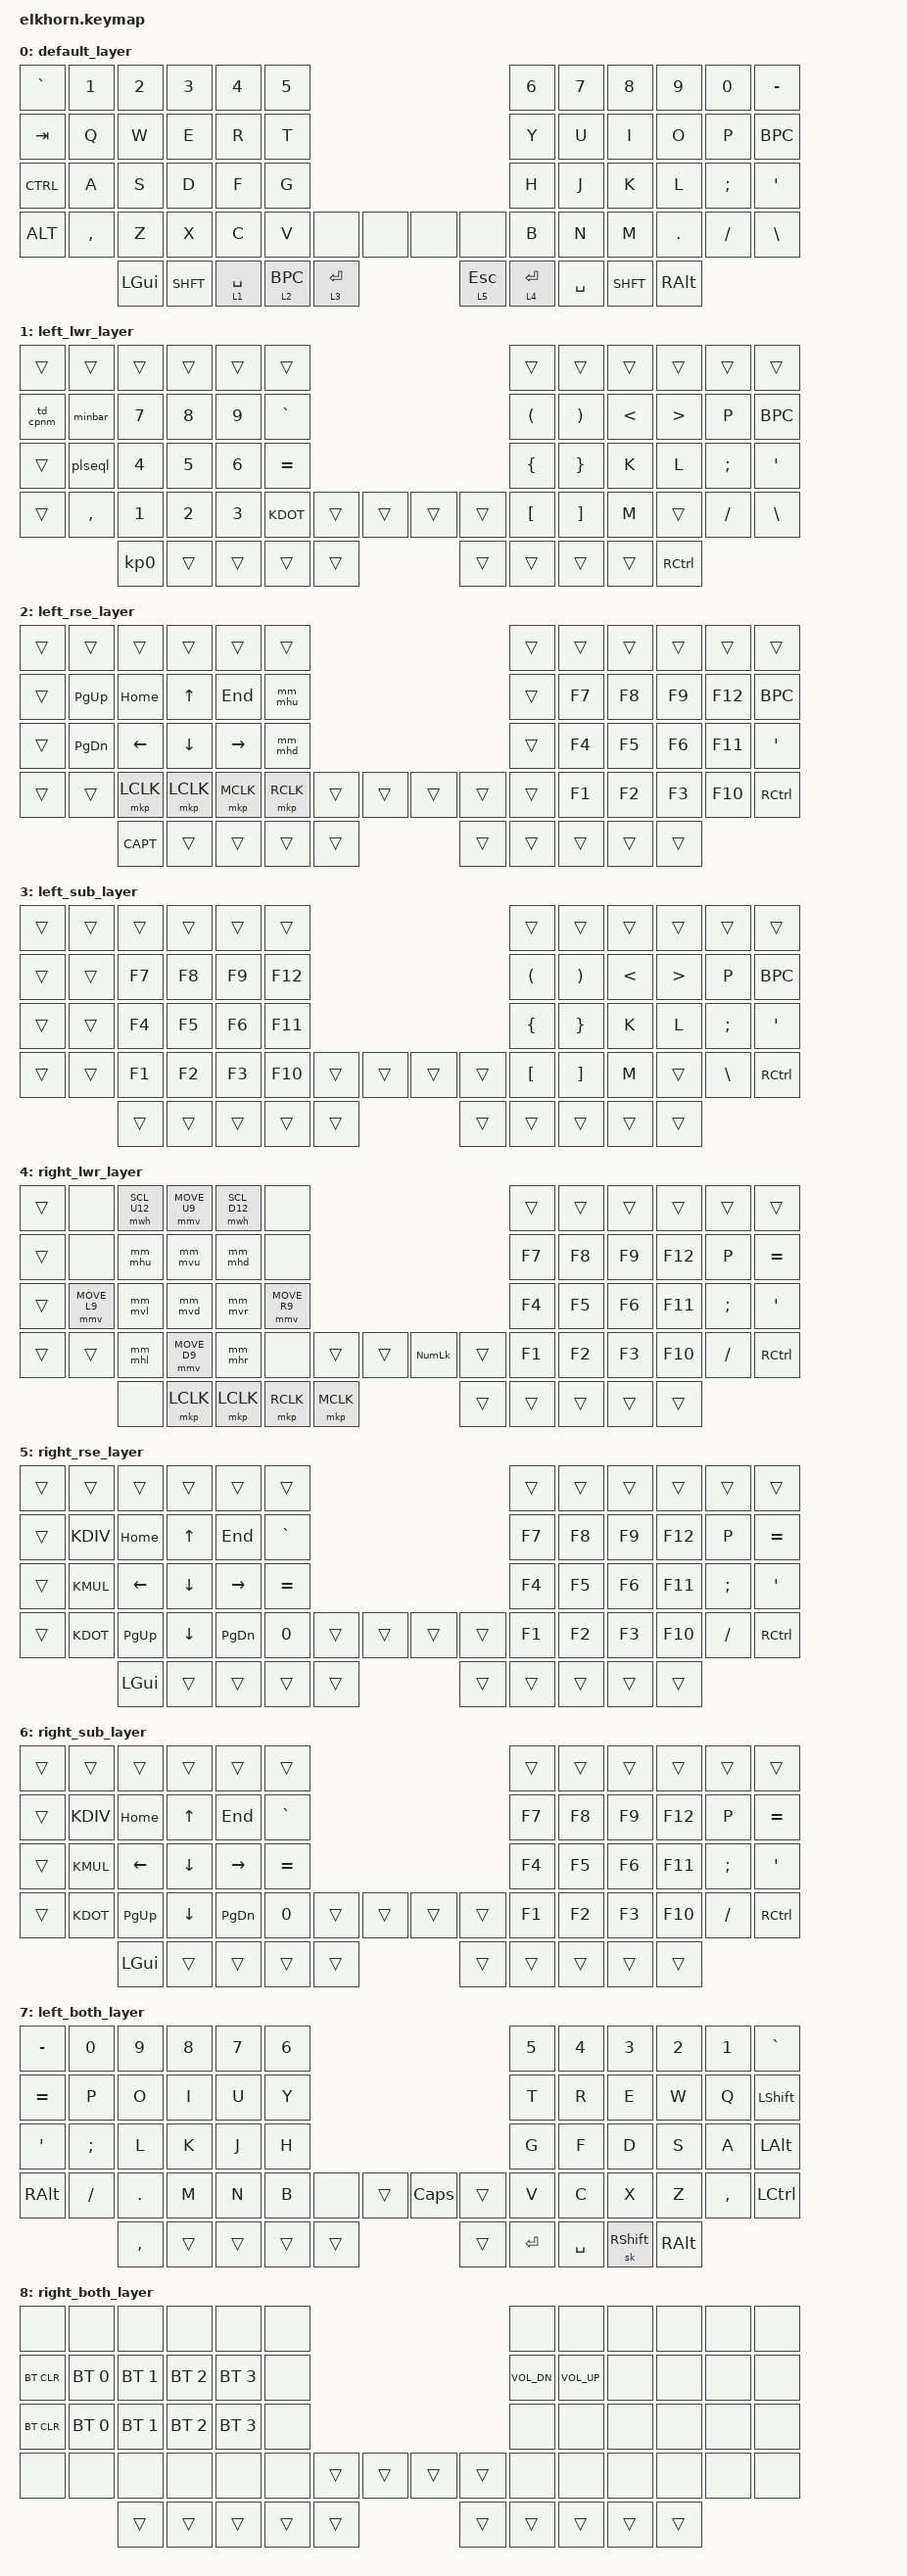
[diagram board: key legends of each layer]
#include <behaviors.dtsi>
#include <dt-bindings/zmk/keys.h>
#include <dt-bindings/zmk/outputs.h>
#include <dt-bindings/zmk/bt.h>
#include <dt-bindings/zmk/mouse.h>

#define HM_TAPPING_TERM 300
#define HM_TAPPING_TERM_FAST 200
#define HM_PRIOR_IDLE 0

#define COMBO_TERM_FAST 35
#define COMBO_TERM_SLOW 40
#define COMBO_PRIOR_IDLE 100

#define MOUSE_MOVE_NEG_DEFAULT -300
#define MOUSE_MOVE_DEFAULT 300
#define MOUSE_MOVE_NEG_FAST -3000 
#define MOUSE_MOVE_FAST 3000 

#define SHFT LSHFT 
#define CTRL LCTRL
#define ALT LALT
#define SPC SPACE
#define BPC BACKSPACE

#define KMIN KP_MINUS
#define KPLS KP_PLUS
#define KMUL KP_MULTIPLY
#define KDIV KP_DIVIDE
#define KDOT KP_DOT
#define KNUM KP_NUM

#define CL CAPS

#define VDN C_VOL_DN
#define VUP C_VOL_UP
#define CALC C_AL_CALC

#define MOVE_U MOVE_VERT(-200)
#define MOVE_D MOVE_VERT(200)
#define MOVE_L MOVE_HOR(-200)
#define MOVE_R MOVE_HOR(200)
#define MOVE_U9 MOVE_VERT(-900)
#define MOVE_D9 MOVE_VERT(900)
#define MOVE_L9 MOVE_HOR(-900)
#define MOVE_R9 MOVE_HOR(900)
#define SCL_U SCROLL_VERT(17)
#define SCL_D SCROLL_VERT(-17)
#define SCL_L SCROLL_HOR(-17)
#define SCL_R SCROLL_HOR(17)
#define SCL_U12 SCROLL_VERT(18)
#define SCL_D12 SCROLL_VERT(-18)
#define SCL_L12 SCROLL_HOR(-18)
#define SCL_R12 SCROLL_HOR(18)



&mmv {
    time-to-max-speed-ms = <0>;
    acceleration-exponent=<0>;
};

&mwh {
    time-to-max-speed-ms = <0>;
    acceleration-exponent=<0>;
};
&mt {
    tapping-term-ms = <100>;
}; 

&sk {
    release-after-ms = <100>;
    quick-release;
}; 

/ {
    chosen {
        zmk,matrix_transform = &default_transform;
    };
};

/ {
    behaviors {
        ht: hold_tab {
            compatible = "zmk,behavior-hold-tap";
            label = "HOLD_TAB";
            #binding-cells = <2>;
            
            flavor = "balanced";
            tapping-term-ms = <HM_TAPPING_TERM_FAST>;
            quick-tap-ms = <0>;
            require-prior-idle-ms = <HM_PRIOR_IDLE>;

            bindings = <&kp>, <&kp>;
        };
        
        hd: hold_mod {
            compatible = "zmk,behavior-hold-tap";
            label = "HOLD_MOD";
            #binding-cells = <2>;
            
            flavor = "balanced";
            tapping-term-ms = <HM_TAPPING_TERM_FAST>;
            quick-tap-ms = <0>;
            require-prior-idle-ms = <HM_PRIOR_IDLE>;

            bindings = <&mo>, <&kp>;
        };

        
        minbar: mod_morph_minus_underbar {
            compatible = "zmk,behavior-mod-morph";
            label="MOD_MORPH_MINUS_UNDERBAR";
            #binding-cells = <0>;
            bindings = <&kp KP_MINUS>, <&kp UNDERSCORE>;
            mods = <(MOD_LSFT)>;
        };
        plseql: mod_morph_plus_equal {
            compatible = "zmk,behavior-mod-morph";
            label="MOD_MORPH_PLUS_EQUAL";
            #binding-cells = <0>;
            bindings = <&kp KP_PLUS>, <&kp EQUAL>;
            mods = <(MOD_LSFT)>;
        };

        td_cpnm: tap_dance_caps_kpnum{
            compatible = "zmk,behavior-tap-dance";
            label = "TAP_DANCE_CAPS_KPNUM";
            #binding-cells = <0>;
            tapping-term-ms = <100>;
            bindings = <&kp CAPS>,  <&kp KP_NUM>;
        };
        
        mm_mvu: mod_morph_mvu{
            compatible = "zmk,behavior-mod-morph";
            label = "MOD_MORPH_MVU";
            #binding-cells = <0>;
            bindings = <&mmv MOVE_VERT(MOUSE_MOVE_NEG_DEFAULT)>,  <&mmv MOVE_VERT(MOUSE_MOVE_NEG_FAST)>;
            mods = <(MOD_LALT)>;
        };
        mm_mvd: mod_morph_mvd{
            compatible = "zmk,behavior-mod-morph";
            label = "MOD_MORPH_MVD";
            #binding-cells = <0>;
            bindings = <&mmv MOVE_VERT(MOUSE_MOVE_DEFAULT)>,  <&mmv MOVE_VERT(MOUSE_MOVE_FAST)>;
            mods = <(MOD_LALT)>;
        };
        mm_mvl: mod_morph_mvl{
            compatible = "zmk,behavior-mod-morph";
            label = "MOD_MORPH_MVL";
            #binding-cells = <0>;
            bindings = <&mmv MOVE_HOR(MOUSE_MOVE_NEG_DEFAULT)>,  <&mmv MOVE_HOR(MOUSE_MOVE_NEG_FAST)>;
            mods = <(MOD_LALT)>;
        };
        mm_mvr: mod_morph_mvr{
            compatible = "zmk,behavior-mod-morph";
            label = "MOD_MORPH_MVR";
            #binding-cells = <0>;
            bindings = <&mmv MOVE_HOR(MOUSE_MOVE_DEFAULT)>,  <&mmv MOVE_HOR(MOUSE_MOVE_FAST)>;
            mods = <(MOD_LALT)>;
        };
        mm_mhu: mod_morph_mhu{
            compatible = "zmk,behavior-mod-morph";
            label = "MOD_MORPH_MHU";
            #binding-cells = <0>;
            bindings = <&mwh SCL_U>,  <&mwh SCL_U12>;
            mods = <(MOD_LALT)>;
        };
        mm_mhd: mod_morph_mhd{
            compatible = "zmk,behavior-mod-morph";
            label = "MOD_MORPH_MHD";
            #binding-cells = <0>;
            bindings = <&mwh SCL_D>,  <&mwh SCL_D12>;
            mods = <(MOD_LALT)>;
        };
        mm_mhl: mod_morph_mhl{
            compatible = "zmk,behavior-mod-morph";
            label = "MOD_MORPH_MHL";
            #binding-cells = <0>;
            bindings = <&mwh SCL_L>,  <&mwh SCL_L12>;
            mods = <(MOD_LALT)>;
        };
        mm_mhr: mod_morph_mhr{
            compatible = "zmk,behavior-mod-morph";
            label = "MOD_MORPH_MHR";
            #binding-cells = <0>;
            bindings = <&mwh SCL_R>,  <&mwh SCL_R12>;
            mods = <(MOD_LALT)>;
        };
    };
    
    conditional_layers {
        compatible = "zmk,conditional-layers";
        left_both_layer {
            if-layers = <1 2>;
            then-layer = <7>;
        };
        right_both_layer {
            if-layers = <4 5>;
            then-layer = <8>;
        };
    };

    
    macros {
        ZMK_MACRO(BTAllClr, wait-ms=<1>; tap-ms=<1>; bindings=<
            &bt BT_SEL 0  &bt BT_CLR &bt BT_SEL 1  &bt BT_CLR &bt BT_SEL 2  &bt BT_CLR 
            &bt BT_SEL 3  &bt BT_CLR &bt BT_SEL 4  &bt BT_CLR >;)
            
        ZMK_MACRO(BTC0, wait-ms=<1>; tap-ms=<1>; bindings=< &bt BT_SEL 0  &bt BT_CLR >;)
        ZMK_MACRO(BTC1, wait-ms=<1>; tap-ms=<1>; bindings=< &bt BT_SEL 1  &bt BT_CLR >;)
        ZMK_MACRO(BTC2, wait-ms=<1>; tap-ms=<1>; bindings=< &bt BT_SEL 2  &bt BT_CLR >;)
        ZMK_MACRO(BTC3, wait-ms=<1>; tap-ms=<1>; bindings=< &bt BT_SEL 3  &bt BT_CLR >;)
        ZMK_MACRO(BTC4, wait-ms=<1>; tap-ms=<1>; bindings=< &bt BT_SEL 4  &bt BT_CLR >;)

        ZMK_MACRO(CAPT ,wait-ms=<30>; tap-ms=<30>; bindings= 
            <&macro_press &kp LSHFT>, <&macro_press &kp LGUI>
            , <&macro_tap &kp S>
            , <&macro_release &kp LSHFT>, <&macro_release &kp LGUI>;)
     };

     combos {
        compatible = "zmk,combos";
        combo_esc {
            timeout-ms = <COMBO_TERM_FAST>;
            require-prior-idle-ms = <COMBO_PRIOR_IDLE>;
            key-positions = <14 15>;
            layers = <0 1>;
            bindings = <&kp ESC>;
        };
        combo_del {
            timeout-ms = <COMBO_TERM_FAST>;
            require-prior-idle-ms = <COMBO_PRIOR_IDLE>;
            key-positions = <15 16>;
            layers = <0 1>;
            bindings = <&kp DEL>;
        };
        combo_enter {
            timeout-ms = <COMBO_TERM_FAST>;
            require-prior-idle-ms = <COMBO_PRIOR_IDLE>;
            key-positions = <26 27>;
            layers = <0 1>;
            bindings = <&kp RET>;
        };
        combo_bspc {
            timeout-ms = <COMBO_TERM_FAST>;
            require-prior-idle-ms = <COMBO_PRIOR_IDLE>;
            key-positions = <27 28>;
            layers = <0 1>;
            bindings = <&kp BSPC>;
        };
        combo_spc {
            timeout-ms = <COMBO_TERM_FAST>;
            require-prior-idle-ms = <COMBO_PRIOR_IDLE>;
            key-positions = <39 40>;
            layers = <0 1>;
            bindings = <&kp SPC>;
        };
        
        combo_mul {
            timeout-ms = <COMBO_TERM_FAST>;
            require-prior-idle-ms = <COMBO_PRIOR_IDLE>;
            key-positions = <25 26>;
            layers = <1>;
            bindings = <&kp KP_MULTIPLY>;
        };
        combo_div {
            timeout-ms = <COMBO_TERM_FAST>;
            require-prior-idle-ms = <COMBO_PRIOR_IDLE>;
            key-positions = <13 14>;
            layers = <1>;
            bindings = <&kp KP_DIVIDE>;
        };
    };
    
/* --------------------------------------------------------------------------------
// | 0  | 1  | 2  | 3  | 4  | 5  |                          | 6  | 7  | 8  | 9  | 10 | 11 |
// | 12 | 13 | 14 | 15 | 16 | 17 |                          | 18 | 19 | 20 | 21 | 22 | 23 |
// | 24 | 25 | 26 | 27 | 28 | 29 |                          | 30 | 31 | 32 | 33 | 34 | 35 |
// | 36 | 37 | 38 | 39 | 40 | 41 | 42 | 43 |      | 44 | 45 | 46 | 47 | 48 | 49 | 50 | 51 |
//           | 52 |    | 53 | 54 | 55 | 56 |      | 57 | 58 | 59 | 60 |    | 61 |
*/
    keymap {
        compatible = "zmk,keymap";

        default_layer { //0
            bindings = <
&kp GRAVE &kp N1    &kp N2    &kp N3    &kp N4    &kp N5                                      &kp N6    &kp N7    &kp N8    &kp N9    &kp N0    &kp MINUS
&kp TAB   &kp Q     &kp W     &kp E     &kp R     &kp T                                       &kp Y     &kp U     &kp I     &kp O     &kp P     &kp BPC
&kp CTRL  &kp A     &kp S     &kp D     &kp F     &kp G                                       &kp H     &kp J     &kp K     &kp L     &kp SEMI  &kp SQT
&kp ALT   &kp COMMA &kp Z     &kp X     &kp C     &kp V     &none    &none    &none &none     &kp B     &kp N     &kp M     &kp DOT   &kp FSLH  &kp BSLH
                    &kp LGUI  &kp SHFT  &hd 1 SPC &hd 2 BPC &hd 3 RET               &hd 5 ESC &hd 4 RET &kp SPC   &kp SHFT  &kp RALT
            >;
        };

        left_lwr_layer { //1
            bindings = <
&trans    &trans    &trans    &trans    &trans    &trans                                      &trans    &trans    &trans    &trans    &trans    &trans
&td_cpnm  &minbar   &kp N7    &kp N8    &kp N9    &kp GRAVE                                   &kp LPAR  &kp RPAR  &kp LT    &kp GT    &kp P     &kp BPC
&trans    &plseql   &kp N4    &kp N5    &kp N6    &kp EQUAL                                   &kp LBRC  &kp RBRC  &kp K     &kp L     &kp SEMI  &kp SQT
&trans    &kp COMMA &kp N1    &kp N2    &kp N3    &kp KDOT  &trans &trans    &trans  &trans   &kp LBKT  &kp RBKT  &kp M     &trans    &kp FSLH  &kp BSLH
                    &kp KP_N0 &trans    &trans    &trans    &trans                   &trans   &trans    &trans  &trans      &kp RCTRL
            >;
        };

        left_rse_layer { //2
            bindings = <
&trans    &trans    &trans    &trans    &trans    &trans                                      &trans    &trans    &trans    &trans    &trans    &trans
&trans    &kp PG_UP &kp HOME  &kp UP    &kp END   &mm_mhu                                     &trans    &kp F7    &kp F8    &kp F9    &kp F12   &kp BPC
&trans    &kp PG_DN &kp LEFT  &kp DOWN  &kp RIGHT &mm_mhd                                     &trans    &kp F4    &kp F5    &kp F6    &kp F11   &kp SQT
&trans    &trans    &mkp LCLK &mkp LCLK &mkp MCLK &mkp RCLK &trans &trans    &trans  &trans   &trans    &kp F1    &kp F2    &kp F3    &kp F10   &kp RCTRL
                    &CAPT     &trans    &trans    &trans    &trans                   &trans   &trans    &trans  &trans    &trans
            >;
        };

        left_sub_layer { //3
            bindings = <
&trans    &trans    &trans    &trans    &trans    &trans                                      &trans    &trans    &trans    &trans    &trans    &trans
&trans    &trans    &kp F7    &kp F8    &kp F9    &kp F12                                     &kp LPAR  &kp RPAR  &kp LT    &kp GT    &kp P     &kp BPC
&trans    &trans    &kp F4    &kp F5    &kp F6    &kp F11                                     &kp LBRC  &kp RBRC  &kp K     &kp L     &kp SEMI  &kp SQT
&trans    &trans    &kp F1    &kp F2    &kp F3    &kp F10   &trans &trans    &trans  &trans   &kp LBKT  &kp RBKT  &kp M     &trans    &kp BSLH  &kp RCTRL
                    &trans    &trans    &trans    &trans    &trans                   &trans   &trans    &trans  &trans    &trans
            >;
        };

        right_lwr_layer { //4
                bindings = <
   &trans    &none         &mwh SCL_U12  &mmv MOVE_U9 &mwh SCL_D12 &none                                         &trans    &trans    &trans    &trans    &trans    &trans
   &trans    &none         &mm_mhu   &mm_mvu  &mm_mhd   &none                                                    &kp F7    &kp F8    &kp F9    &kp F12   &kp P     &kp EQUAL
   &trans    &mmv MOVE_L9  &mm_mvl   &mm_mvd  &mm_mvr  &mmv MOVE_R9                                              &kp F4    &kp F5    &kp F6    &kp F11   &kp SEMI  &kp SQT
   &trans    &trans        &mm_mhl   &mmv MOVE_D9   &mm_mhr  &none    &trans     &trans      &kp KP_NUM &trans   &kp F1    &kp F2    &kp F3    &kp F10   &kp FSLH  &kp RCTRL
                           &none     &mkp LCLK   &mkp LCLK   &mkp RCLK  &mkp MCLK                       &trans   &trans    &trans    &trans    &trans
            >;
        };

        right_rse_layer { //5
            bindings = <
&trans    &trans    &trans    &trans    &trans    &trans                                      &trans    &trans    &trans    &trans    &trans    &trans
&trans    &kp KDIV  &kp HOME  &kp UP    &kp END   &kp GRAVE                                   &kp F7    &kp F8    &kp F9    &kp F12   &kp P     &kp EQUAL
&trans    &kp KMUL  &kp LEFT  &kp DOWN  &kp RIGHT &kp EQUAL                                   &kp F4    &kp F5    &kp F6    &kp F11   &kp SEMI  &kp SQT
&trans    &kp KDOT  &kp PG_UP &kp DOWN  &kp PG_DN &kp N0    &trans &trans    &trans  &trans   &kp F1    &kp F2    &kp F3    &kp F10   &kp FSLH  &kp RCTRL
                    &kp LGUI  &trans    &trans    &trans    &trans                   &trans   &trans    &trans  &trans    &trans
            >;
        };

        right_sub_layer { //6
            bindings = <
&trans    &trans    &trans    &trans    &trans    &trans                                      &trans    &trans    &trans    &trans    &trans    &trans
&trans    &kp KDIV  &kp HOME  &kp UP    &kp END   &kp GRAVE                                   &kp F7    &kp F8    &kp F9    &kp F12   &kp P     &kp EQUAL
&trans    &kp KMUL  &kp LEFT  &kp DOWN  &kp RIGHT &kp EQUAL                                   &kp F4    &kp F5    &kp F6    &kp F11   &kp SEMI  &kp SQT
&trans    &kp KDOT  &kp PG_UP &kp DOWN  &kp PG_DN &kp N0    &trans &trans    &trans  &trans   &kp F1    &kp F2    &kp F3    &kp F10   &kp FSLH  &kp RCTRL
                    &kp LGUI  &trans    &trans    &trans    &trans                   &trans   &trans    &trans  &trans    &trans
            >;
        };
        
        left_both_layer { //7
            bindings = <
   &kp MINUS  &kp N0    &kp N9    &kp N8    &kp N7    &kp N6                                                     &kp N5     &kp N4     &kp N3     &kp N2    &kp N1    &kp GRAVE
   &kp EQUAL  &kp P     &kp O     &kp I     &kp U     &kp Y                                                      &kp T      &kp R      &kp E      &kp W     &kp Q     &kp LSHFT
   &kp SQT    &kp SEMI  &kp L     &kp K     &kp J     &kp H                                                      &kp G      &kp F      &kp D      &kp S     &kp A     &kp LALT
   &kp RALT   &kp FSLH  &kp DOT   &kp M     &kp N     &kp B     &none       &trans             &kp CAPS  &trans  &kp V      &kp C      &kp X      &kp Z     &kp COMMA &kp LCTRL   
                        &kp COMMA &trans    &trans    &trans   &trans                                    &trans  &kp RET   &kp SPACE   &sk RSHFT  &kp RALT
            >;
        };

        
        right_both_layer { // 8
            bindings = <
&none        &none        &none        &none        &none        &none                                              &none      &none      &none     &none     &none     &none
&bt BT_CLR   &bt BT_SEL 0 &bt BT_SEL 1 &bt BT_SEL 2 &bt BT_SEL 3 &none                                              &kp C_VOL_DN &kp C_VOL_UP &none &none     &none     &none
&bt BT_CLR   &bt BT_SEL 0 &bt BT_SEL 1 &bt BT_SEL 2 &bt BT_SEL 3 &none                                              &none      &none      &none     &none     &none     &none 
&none        &none        &none        &none        &none        &none     &trans   &trans        &trans   &trans   &none      &none      &none     &none     &none     &none
                          &trans       &trans       &trans       &trans    &trans                          &trans   &trans     &trans     &trans    &trans
            >;
        };
    };
};
